# S6E1A1 register map
File version: 1.2
CPU: 
Registers are 32-bit, read-write, reset 0x0 unless marked. A register's access mark holds for its fields unless they carry their own. Offsets are from the block's base; [hi:lo] are bit positions.

## INTREQ — Interrupts
Base 0x40031000
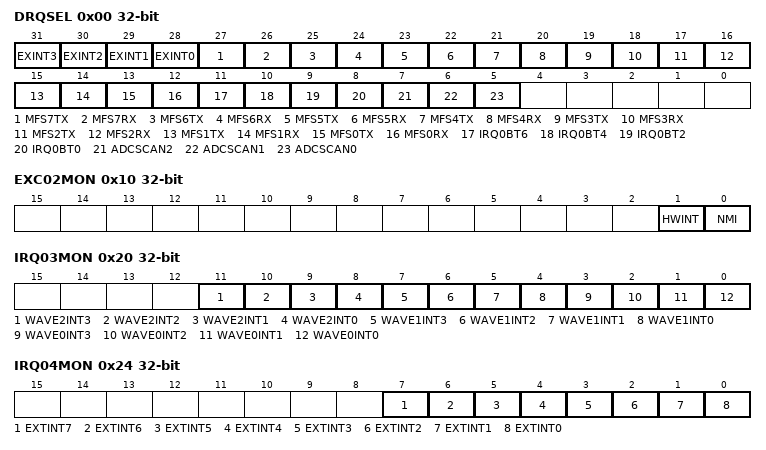
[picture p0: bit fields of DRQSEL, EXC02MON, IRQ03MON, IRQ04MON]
0x00 DRQSEL — DMA Request Selection Register
  [31] EXINT3 — The interrupt signal of the external interrupt ch.3 is output as a transfer request to the DMAC
  [30] EXINT2 — The interrupt signal of the external interrupt ch.2 is output as a transfer request to the DMAC
  [29] EXINT1 — The interrupt signal of the external interrupt ch.1 is output as a transfer request to the DMAC
  [28] EXINT0 — The interrupt signal of the external interrupt ch.0 is output as a transfer request to the DMAC
  [27] MFS7TX — The transmission interrupt signal of the MFS ch.7 is output as a transfer request to the DMAC
  [26] MFS7RX — The reception interrupt signal of the MFS ch.7 is output as a transfer request to the DMAC
  [25] MFS6TX — The transmission interrupt signal of the MFS ch.6 is output as a transfer request to the DMAC
  [24] MFS6RX — The reception interrupt signal of the MFS ch.6 is output as a transfer request to the DMAC
  [23] MFS5TX — The transmission interrupt signal of the MFS ch.5 is output as a transfer request to the DMAC
  [22] MFS5RX — The reception interrupt signal of the MFS ch.5 is output as a transfer request to the DMAC
  [21] MFS4TX — The transmission interrupt signal of the MFS ch.4 is output as a transfer request to the DMAC
  [20] MFS4RX — The reception interrupt signal of the MFS ch.4 is output as a transfer request to the DMAC
  [19] MFS3TX — The transmission interrupt signal of the MFS ch.3 is output as a transfer request to the DMAC
  [18] MFS3RX — The reception interrupt signal of the MFS ch.3 is output as a transfer request to the DMAC
  [17] MFS2TX — The transmission interrupt signal of the MFS ch.2 is output as a transfer request to the DMAC
  [16] MFS2RX — The reception interrupt signal of the MFS ch.2 is output as a transfer request to the DMAC
  [15] MFS1TX — The transmission interrupt signal of the MFS ch.1 is output as a transfer request to the DMAC
  [14] MFS1RX — The reception interrupt signal of the MFS ch.1 is output as a transfer request to the DMAC
  [13] MFS0TX — The transmission interrupt signal of the MFS ch.0 is output as a transfer request to the DMAC
  [12] MFS0RX — The reception interrupt signal of the MFS ch.0 is output as a transfer request to the DMAC
  [11] IRQ0BT6 — The IRQ0 interrupt signal of the base timer ch.6 is output as a transfer request to the DMAC
  [10] IRQ0BT4 — The IRQ0 interrupt signal of the base timer ch.4 is output as a transfer request to the DMAC
  [9] IRQ0BT2 — The IRQ0 interrupt signal of the base timer ch.2 is output as a transfer request to the DMAC
  [8] IRQ0BT0 — The IRQ0 interrupt signal of the base timer ch.0 is output as a transfer request to the DMAC
  [7] ADCSCAN2 — The scan conversion interrupt signal of the A/D converter unit 2 is output as a transfer request to the DMAC
  [6] ADCSCAN1 — The scan conversion interrupt signal of the A/D converter unit 1 is output as a transfer request to the DMAC
  [5] ADCSCAN0 — The scan conversion interrupt signal of the A/D converter unit 0 is output as a transfer request to the DMAC
0x0C IRQCMODE — Interrupt Factor Vector Relocate Setting Register
  [0] IRQCMODE — Assigns the interrupt factor vector according to Table 1-1 in chapter "Interrupt B"
0x10 EXC02MON ro — EXC02 Batch Read Register
  [1] HWINT — Hardware watchdog timer interrupt request
  [0] NMI — NMIX external pin interrupt request
0x14 IRQ00MON ro — IRQ00 Batch Read Register
  [0] FCSINT — Anomalous frequency detection by CSV interrupt request
0x18 IRQ01MON ro — IRQ01 Batch Read Register
  [0] SWWDTINT — Software watchdog timer interrupt request
0x1C IRQ02MON ro — IRQ02 Batch Read Register
  [0] LVDINT — Low voltage detection (LVD) interrupt request
0x20 IRQ03MON ro — IRQ03 Batch Read Register
  [11] WAVE2INT3 — WFG timer 54 interrupt request in MFT unit 2
  [10] WAVE2INT2 — WFG timer 32 interrupt request in MFT unit 2
  [9] WAVE2INT1 — WFG timer 10 interrupt request in MFT unit 2
  [8] WAVE2INT0 — DTIF (motor emergency stop) interrupt request in MFT unit 2
  [7] WAVE1INT3 — WFG timer 54 interrupt request in MFT unit 1
  [6] WAVE1INT2 — WFG timer 32 interrupt request in MFT unit 1
  [5] WAVE1INT1 — WFG timer 10 interrupt request in MFT unit 1
  [4] WAVE1INT0 — DTIF (motor emergency stop) interrupt request in MFT unit 1
  [3] WAVE0INT3 — WFG timer 54 interrupt request in MFT unit 0
  [2] WAVE0INT2 — WFG timer 32 interrupt request in MFT unit 0
  [1] WAVE0INT1 — WFG timer 10 interrupt request in MFT unit 0
  [0] WAVE0INT0 — DTIF (motor emergency stop) interrupt request in MFT unit 0
0x24 IRQ04MON ro — IRQ04 Batch Read Register
  [7] EXTINT7 — Interrupt request of external interrupt ch.7
  [6] EXTINT6 — Interrupt request of external interrupt ch.6
  [5] EXTINT5 — Interrupt request of external interrupt ch.5
  [4] EXTINT4 — Interrupt request of external interrupt ch.4
  [3] EXTINT3 — Interrupt request of external interrupt ch.3
  [2] EXTINT2 — Interrupt request of external interrupt ch.2
  [1] EXTINT1 — Interrupt request of external interrupt ch.1
  [0] EXTINT0 — Interrupt request of external interrupt ch.0
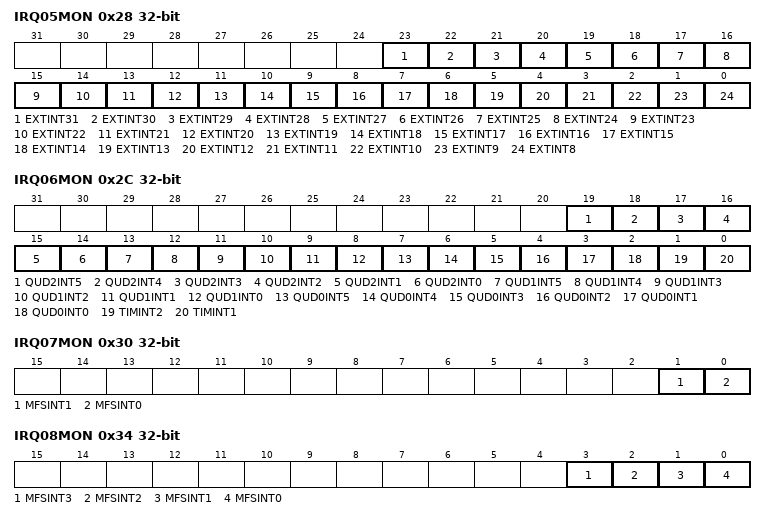
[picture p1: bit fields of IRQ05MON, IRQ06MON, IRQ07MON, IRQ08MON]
0x28 IRQ05MON ro — IRQ05 Batch Read Register
  [23] EXTINT31 — Interrupt request of external interrupt ch.31
  [22] EXTINT30 — Interrupt request of external interrupt ch.30
  [21] EXTINT29 — Interrupt request of external interrupt ch.29
  [20] EXTINT28 — Interrupt request of external interrupt ch.28
  [19] EXTINT27 — Interrupt request of external interrupt ch.27
  [18] EXTINT26 — Interrupt request of external interrupt ch.26
  [17] EXTINT25 — Interrupt request of external interrupt ch.25
  [16] EXTINT24 — Interrupt request of external interrupt ch.24
  [15] EXTINT23 — Interrupt request of external interrupt ch.23
  [14] EXTINT22 — Interrupt request of external interrupt ch.22
  [13] EXTINT21 — Interrupt request of external interrupt ch.21
  [12] EXTINT20 — Interrupt request of external interrupt ch.20
  [11] EXTINT19 — Interrupt request of external interrupt ch.19
  [10] EXTINT18 — Interrupt request of external interrupt ch.18
  [9] EXTINT17 — Interrupt request of external interrupt ch.17
  [8] EXTINT16 — Interrupt request of external interrupt ch.16
  [7] EXTINT15 — Interrupt request of external interrupt ch.15
  [6] EXTINT14 — Interrupt request of external interrupt ch.14
  [5] EXTINT13 — Interrupt request of external interrupt ch.13
  [4] EXTINT12 — Interrupt request of external interrupt ch.12
  [3] EXTINT11 — Interrupt request of external interrupt ch.11
  [2] EXTINT10 — Interrupt request of external interrupt ch.10
  [1] EXTINT9 — Interrupt request of external interrupt ch.9
  [0] EXTINT8 — Interrupt request of external interrupt ch.8
0x2C IRQ06MON ro — IRQ06 Batch Read Register
  [19] QUD2INT5 — PC match and RC match interrupt request of QPRC ch.2
  [18] QUD2INT4 — Interrupt request detected RC out of range of QPRC ch.2
  [17] QUD2INT3 — PC count invert interrupt request of QPRC ch.2
  [16] QUD2INT2 — Overflow/underflow/zero index interrupt request of QPRC ch.2
  [15] QUD2INT1 — PC and RC match interrupt request of QPRC ch.2
  [14] QUD2INT0 — PC match interrupt request of QPRC ch.2
  [13] QUD1INT5 — PC match and RC match interrupt request of QPRC ch.1
  [12] QUD1INT4 — Interrupt request detected RC out of range of QPRC ch.1
  [11] QUD1INT3 — PC count invert interrupt request of QPRC ch.1
  [10] QUD1INT2 — Overflow/underflow/zero index interrupt request of QPRC ch.1
  [9] QUD1INT1 — PC and RC match interrupt request of QPRC ch.1
  [8] QUD1INT0 — PC match interrupt request of QPRC ch.1
  [7] QUD0INT5 — PC match and RC match interrupt request of QPRC ch.0
  [6] QUD0INT4 — Interrupt request detected RC out of range of QPRC ch.0
  [5] QUD0INT3 — PC count invert interrupt request of QPRC ch.0
  [4] QUD0INT2 — Overflow/underflow/zero index interrupt request of QPRC ch.0
  [3] QUD0INT1 — PC and RC match interrupt request of QPRC ch.0
  [2] QUD0INT0 — PC match interrupt request of QPRC ch.0
  [1] TIMINT2 — Dual timer TIMINT2 interrupt request
  [0] TIMINT1 — Dual timer TIMINT1 interrupt request
0x30 IRQ07MON ro — IRQ07 Batch Read Register
  [1] MFSINT1 — Reception interrupt request of MFS channel 8
  [0] MFSINT0 — Reception interrupt request of MFS channel 0
0x34 IRQ08MON ro — IRQ08 Batch Read Register
  [3] MFSINT3 — Status interrupt request of MFS channel 8
  [2] MFSINT2 — Transmission interrupt request of MFS channel 8
  [1] MFSINT1 — Status interrupt request of MFS channel 0
  [0] MFSINT0 — Transmission interrupt request of MFS channel 0
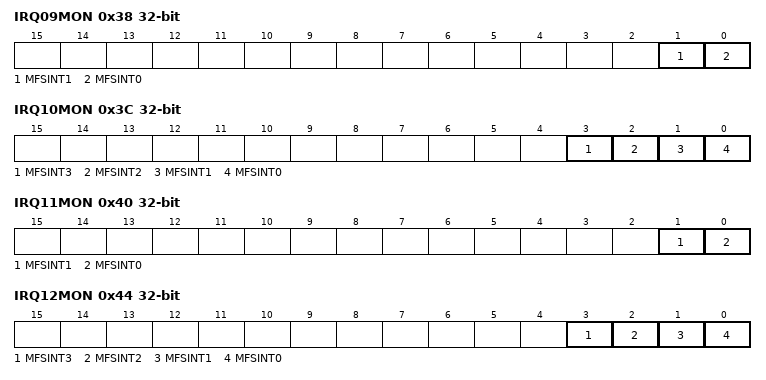
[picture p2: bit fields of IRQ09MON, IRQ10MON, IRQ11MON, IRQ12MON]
0x38 IRQ09MON ro — IRQ09 Batch Read Register
  [1] MFSINT1 — Reception interrupt request of MFS channel 9
  [0] MFSINT0 — Reception interrupt request of MFS channel 1
0x3C IRQ10MON ro — IRQ10 Batch Read Register
  [3] MFSINT3 — Status interrupt request of MFS channel 9
  [2] MFSINT2 — Transmission interrupt request of MFS channel 9
  [1] MFSINT1 — Status interrupt request of MFS channel 1
  [0] MFSINT0 — Transmission interrupt request of MFS channel 1
0x40 IRQ11MON ro — IRQ11 Batch Read Register
  [1] MFSINT1 — Reception interrupt request of MFS channel 10
  [0] MFSINT0 — Reception interrupt request of MFS channel 2
0x44 IRQ12MON ro — IRQ12 Batch Read Register
  [3] MFSINT3 — Status interrupt request of MFS channel 10
  [2] MFSINT2 — Transmission interrupt request of MFS channel 10
  [1] MFSINT1 — Status interrupt request of MFS channel 2
  [0] MFSINT0 — Transmission interrupt request of MFS channel 2
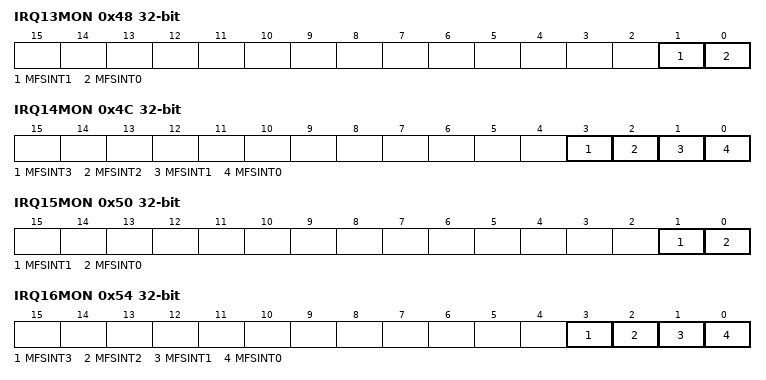
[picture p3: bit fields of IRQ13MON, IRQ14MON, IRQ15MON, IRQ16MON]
0x48 IRQ13MON ro — IRQ13 Batch Read Register
  [1] MFSINT1 — Reception interrupt request of MFS channel 11
  [0] MFSINT0 — Reception interrupt request of MFS channel 3
0x4C IRQ14MON ro — IRQ14 Batch Read Register
  [3] MFSINT3 — Status interrupt request of MFS channel 11
  [2] MFSINT2 — Transmission interrupt request of MFS channel 11
  [1] MFSINT1 — Status interrupt request of MFS channel 3
  [0] MFSINT0 — Transmission interrupt request of MFS channel 3
0x50 IRQ15MON ro — IRQ15 Batch Read Register
  [1] MFSINT1 — Reception interrupt request of MFS channel 12
  [0] MFSINT0 — Reception interrupt request of MFS channel 4
0x54 IRQ16MON ro — IRQ16 Batch Read Register
  [3] MFSINT3 — Status interrupt request of MFS channel 12
  [2] MFSINT2 — Transmission interrupt request of MFS channel 12
  [1] MFSINT1 — Status interrupt request of MFS channel 4
  [0] MFSINT0 — Transmission interrupt request of MFS channel 4
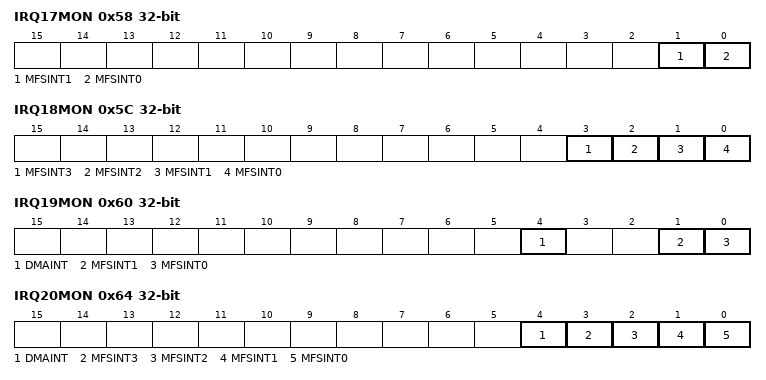
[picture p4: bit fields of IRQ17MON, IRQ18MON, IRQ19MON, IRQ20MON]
0x58 IRQ17MON ro — IRQ17 Batch Read Register
  [1] MFSINT1 — Reception interrupt request of MFS channel 13
  [0] MFSINT0 — Reception interrupt request of MFS channel 5
0x5C IRQ18MON ro — IRQ18 Batch Read Register
  [3] MFSINT3 — Status interrupt request of MFS channel 13
  [2] MFSINT2 — Transmission interrupt request of MFS channel 13
  [1] MFSINT1 — Status interrupt request of MFS channel 5
  [0] MFSINT0 — Transmission interrupt request of MFS channel 5
0x60 IRQ19MON ro — IRQ19 Batch Read Register
  [4] DMAINT — Interrupt request of DMAC ch.0
  [1] MFSINT1 — Reception interrupt request of MFS channel 14
  [0] MFSINT0 — Reception interrupt request of MFS channel 6
0x64 IRQ20MON ro — IRQ20 Batch Read Register
  [4] DMAINT — Interrupt request of DMAC ch.1
  [3] MFSINT3 — Status interrupt request of MFS channel 14
  [2] MFSINT2 — Transmission interrupt request of MFS channel 14
  [1] MFSINT1 — Status interrupt request of MFS channel 6
  [0] MFSINT0 — Transmission interrupt request of MFS channel 6
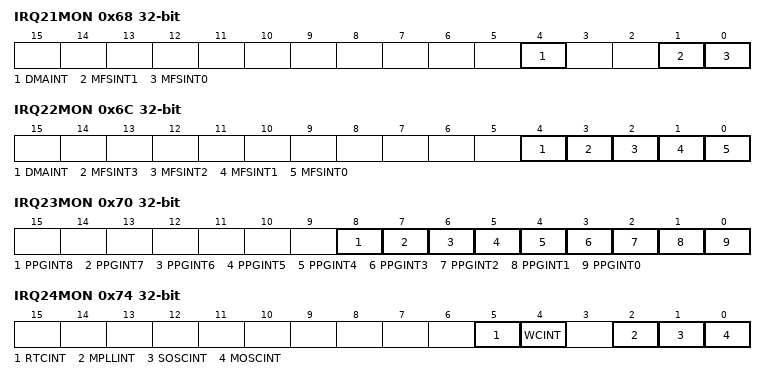
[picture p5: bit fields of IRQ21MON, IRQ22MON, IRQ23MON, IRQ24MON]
0x68 IRQ21MON ro — IRQ21 Batch Read Register
  [4] DMAINT — Interrupt request of DMAC ch.2
  [1] MFSINT1 — Reception interrupt request of MFS channel 15
  [0] MFSINT0 — Reception interrupt request of MFS channel 7
0x6C IRQ22MON ro — IRQ22 Batch Read Register
  [4] DMAINT — Interrupt request of DMAC ch.3
  [3] MFSINT3 — Status interrupt request of MFS channel 15
  [2] MFSINT2 — Transmission interrupt request of MFS channel 15
  [1] MFSINT1 — Status interrupt request of MFS channel 7
  [0] MFSINT0 — Transmission interrupt request of MFS channel 7
0x70 IRQ23MON ro — IRQ23 Batch Read Register
  [8] PPGINT8 — Interrupt request of PPG ch.20
  [7] PPGINT7 — Interrupt request of PPG ch.18
  [6] PPGINT6 — Interrupt request of PPG ch.16
  [5] PPGINT5 — Interrupt request of PPG ch.12
  [4] PPGINT4 — Interrupt request of PPG ch.10
  [3] PPGINT3 — Interrupt request of PPG ch.8
  [2] PPGINT2 — Interrupt request of PPG ch.4
  [1] PPGINT1 — Interrupt request of PPG ch.2
  [0] PPGINT0 — Interrupt request of PPG ch.0
0x74 IRQ24MON ro — IRQ24 Batch Read Register
  [5] RTCINT — RTC interrupt request
  [4] WCINT — Watch counter interrupt request
  [2] MPLLINT — Stabilization wait completion interrupt request for main PLL oscillation
  [1] SOSCINT — Stabilization wait completion interrupt request for sub-clock oscillation
  [0] MOSCINT — Stabilization wait completion interrupt request for main clock oscillation
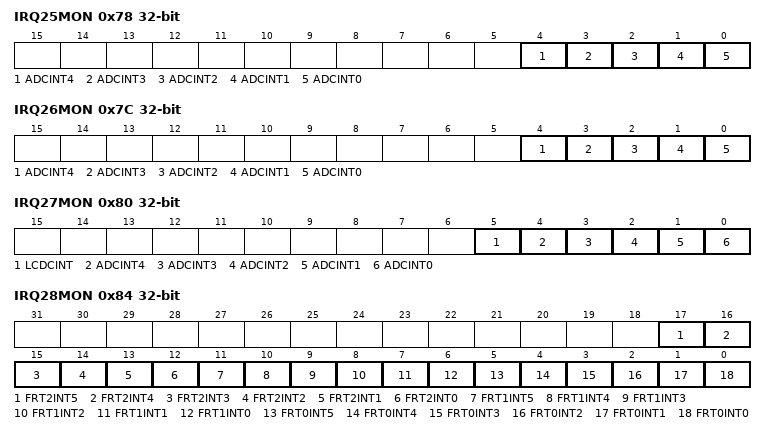
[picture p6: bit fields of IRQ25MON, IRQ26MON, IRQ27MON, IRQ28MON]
0x78 IRQ25MON ro — IRQ25 Batch Read Register
  [4] ADCINT4 — Range comparison result interrupt request in the A/D converter unit 0
  [3] ADCINT3 — Conversion result comparison interrupt request in the A/D converter unit 0
  [2] ADCINT2 — FIFO overrun interrupt request in the A/D converter unit 0
  [1] ADCINT1 — Scan conversion interrupt request in the A/D converter unit 0
  [0] ADCINT0 — Priority conversion interrupt request in the A/D converter unit 0
0x7C IRQ26MON ro — IRQ26 Batch Read Register
  [4] ADCINT4 — Range comparison result interrupt request in the A/D converter unit 1
  [3] ADCINT3 — Conversion result comparison interrupt request in the A/D converter unit 1
  [2] ADCINT2 — FIFO overrun interrupt request in the A/D converter unit 1
  [1] ADCINT1 — Scan conversion interrupt request in the A/D converter unit 1
  [0] ADCINT0 — Priority conversion interrupt request in the A/D converter unit 1
0x80 IRQ27MON ro — IRQ27 Batch Read Register
  [5] LCDCINT — Interrupt request for LCD controller
  [4] ADCINT4 — Range comparison result interrupt request in the A/D converter unit 2
  [3] ADCINT3 — Conversion result comparison interrupt request in the A/D converter unit 2
  [2] ADCINT2 — FIFO overrun interrupt request in the A/D converter unit 2
  [1] ADCINT1 — Scan conversion interrupt request in the A/D converter unit 2
  [0] ADCINT0 — Priority conversion interrupt request in the A/D converter unit 2
0x84 IRQ28MON ro — IRQ28 Batch Read Register
  [17] FRT2INT5 — Zero detection interrupt request of the free run timer ch.2 in the MFT unit 2
  [16] FRT2INT4 — Zero detection interrupt request of the free run timer ch.1 in the MFT unit 2
  [15] FRT2INT3 — Zero detection interrupt request of the free run timer ch.0 in the MFT unit 2
  [14] FRT2INT2 — Peak value detection interrupt request of the free run timer ch.2 in the MFT unit 2
  [13] FRT2INT1 — Peak value detection interrupt request of the free run timer ch.1 in the MFT unit 2
  [12] FRT2INT0 — Peak value detection interrupt request of the free run timer ch.0 in the MFT unit 2
  [11] FRT1INT5 — Zero detection interrupt request of the free run timer ch.2 in the MFT unit 1
  [10] FRT1INT4 — Zero detection interrupt request of the free run timer ch.1 in the MFT unit 1
  [9] FRT1INT3 — Zero detection interrupt request of the free run timer ch.0 in the MFT unit 1
  [8] FRT1INT2 — Peak value detection interrupt request of the free run timer ch.2 in the MFT unit 1
  [7] FRT1INT1 — Peak value detection interrupt request of the free run timer ch.1 in the MFT unit 1
  [6] FRT1INT0 — Peak value detection interrupt request of the free run timer ch.0 in the MFT unit 1
  [5] FRT0INT5 — Zero detection interrupt request of the free run timer ch.2 in the MFT unit 0
  [4] FRT0INT4 — Zero detection interrupt request of the free run timer ch.1 in the MFT unit 0
  [3] FRT0INT3 — Zero detection interrupt request of the free run timer ch.0 in the MFT unit 0
  [2] FRT0INT2 — Peak value detection interrupt request of the free run timer ch.2 in the MFT unit 0
  [1] FRT0INT1 — Peak value detection interrupt request of the free run timer ch.1 in the MFT unit 0
  [0] FRT0INT0 — Peak value detection interrupt request of the free run timer ch.0 in the MFT unit 0
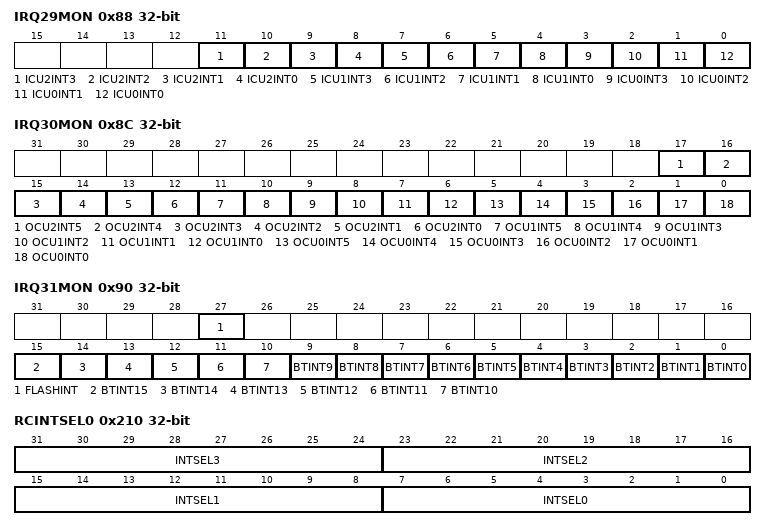
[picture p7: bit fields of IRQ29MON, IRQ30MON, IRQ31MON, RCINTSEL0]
0x88 IRQ29MON ro — IRQ29 Batch Read Register
  [11] ICU2INT3 — Interrupt request of the input capture ch.3 in the MFT unit 2
  [10] ICU2INT2 — Interrupt request of the input capture ch.2 in the MFT unit 2
  [9] ICU2INT1 — Interrupt request of the input capture ch.1 in the MFT unit 2
  [8] ICU2INT0 — Interrupt request of the input capture ch.0 in the MFT unit 2
  [7] ICU1INT3 — Interrupt request of the input capture ch.3 in the MFT unit 1
  [6] ICU1INT2 — Interrupt request of the input capture ch.2 in the MFT unit 1
  [5] ICU1INT1 — Interrupt request of the input capture ch.1 in the MFT unit 1
  [4] ICU1INT0 — Interrupt request of the input capture ch.0 in the MFT unit 1
  [3] ICU0INT3 — Interrupt request of the input capture ch.3 in the MFT unit 0
  [2] ICU0INT2 — Interrupt request of the input capture ch.2 in the MFT unit 0
  [1] ICU0INT1 — Interrupt request of the input capture ch.1 in the MFT unit 0
  [0] ICU0INT0 — Interrupt request of the input capture ch.0 in the MFT unit 0
0x8C IRQ30MON ro — IRQ30 Batch Read Register
  [17] OCU2INT5 — Interrupt request of the output compare ch.5 in the MFT unit 2
  [16] OCU2INT4 — Interrupt request of the output compare ch.4 in the MFT unit 2
  [15] OCU2INT3 — Interrupt request of the output compare ch.3 in the MFT unit 2
  [14] OCU2INT2 — Interrupt request of the output compare ch.2 in the MFT unit 2
  [13] OCU2INT1 — Interrupt request of the output compare ch.1 in the MFT unit 2
  [12] OCU2INT0 — Interrupt request of the output compare ch.0 in the MFT unit 2
  [11] OCU1INT5 — Interrupt request of the output compare ch.5 in the MFT unit 1
  [10] OCU1INT4 — Interrupt request of the output compare ch.4 in the MFT unit 1
  [9] OCU1INT3 — Interrupt request of the output compare ch.3 in the MFT unit 1
  [8] OCU1INT2 — Interrupt request of the output compare ch.2 in the MFT unit 1
  [7] OCU1INT1 — Interrupt request of the output compare ch.1 in the MFT unit 1
  [6] OCU1INT0 — Interrupt request of the output compare ch.0 in the MFT unit 1
  [5] OCU0INT5 — Interrupt request of the output compare ch.5 in the MFT unit 0
  [4] OCU0INT4 — Interrupt request of the output compare ch.4 in the MFT unit 0
  [3] OCU0INT3 — Interrupt request of the output compare ch.3 in the MFT unit 0
  [2] OCU0INT2 — Interrupt request of the output compare ch.2 in the MFT unit 0
  [1] OCU0INT1 — Interrupt request of the output compare ch.1 in the MFT unit 0
  [0] OCU0INT0 — Interrupt request of the output compare ch.0 in the MFT unit 0
0x90 IRQ31MON ro — IRQ31 Batch Read Register
  [27] FLASHINT — RDY/HANG interrupt request for f lash memory
  [15] BTINT15 — IRQ1 interrupt request of the base timer ch.7
  [14] BTINT14 — IRQ0 interrupt request of the base timer ch.7
  [13] BTINT13 — IRQ1 interrupt request of the base timer ch.6
  [12] BTINT12 — IRQ0 interrupt request of the base timer ch.6
  [11] BTINT11 — IRQ1 interrupt request of the base timer ch.5
  [10] BTINT10 — IRQ0 interrupt request of the base timer ch.5
  [9] BTINT9 — IRQ1 interrupt request of the base timer ch.4
  [8] BTINT8 — IRQ0 interrupt request of the base timer ch.4
  [7] BTINT7 — IRQ1 interrupt request of the base timer ch.3
  [6] BTINT6 — IRQ0 interrupt request of the base timer ch.3
  [5] BTINT5 — IRQ1 interrupt request of the base timer ch.2
  [4] BTINT4 — IRQ0 interrupt request of the base timer ch.2
  [3] BTINT3 — IRQ1 interrupt request of the base timer ch.1
  [2] BTINT2 — IRQ0 interrupt request of the base timer ch.1
  [1] BTINT1 — IRQ1 interrupt request of the base timer ch.0
  [0] BTINT0 — IRQ0 interrupt request of the base timer ch.0
0x210 RCINTSEL0 — Interrupt Factor Selection Register 0
  [31:24] INTSEL3 — Select the interrupt factor for the interrupt vector No.22
  [23:16] INTSEL2 — Select the interrupt factor for the interrupt vector No.21
  [15:8] INTSEL1 — Select the interrupt factor for the interrupt vector No.20
  [7:0] INTSEL0 — Select the interrupt factor for the interrupt vector No.19
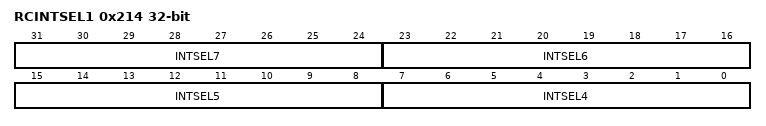
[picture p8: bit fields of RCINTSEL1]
0x214 RCINTSEL1 — Interrupt Factor Selection Register 1
  [31:24] INTSEL7 — Select the interrupt factor for the interrupt vector No.26
  [23:16] INTSEL6 — Select the interrupt factor for the interrupt vector No.25
  [15:8] INTSEL5 — Select the interrupt factor for the interrupt vector No.24
  [7:0] INTSEL4 — Select the interrupt factor for the interrupt vector No.23
